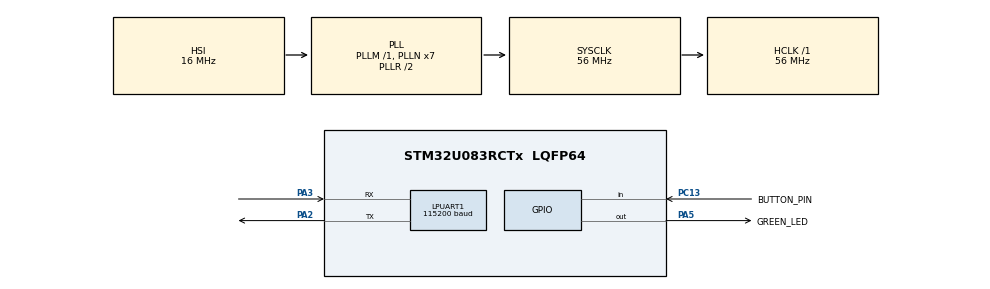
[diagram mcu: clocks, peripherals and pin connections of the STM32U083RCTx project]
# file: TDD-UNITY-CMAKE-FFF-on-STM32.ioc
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LPUART1.BaudRate=115200
Mcu.Family=STM32U0
Mcu.Name=STM32U083RCTx
Mcu.Package=LQFP64
NVIC.PriorityGroup=NVIC_PRIORITYGROUP_2
PA13\ (SWDIO).GPIO_Label=SWDIO
PA13\ (SWDIO).Mode=Serial_Wire
PA13\ (SWDIO).Signal=DEBUG_JTMS-SWDIO
PA14\ (SWCLK).GPIO_Label=SWCLK
PA14\ (SWCLK).Mode=Serial_Wire
PA14\ (SWCLK).Signal=DEBUG_JTCK-SWCLK
PA2.Mode=Asynchronous
PA2.Signal=LPUART1_TX
PA3.Mode=Asynchronous
PA3.Signal=LPUART1_RX
PA5.GPIO_Label=GREEN_LED
PA5.Signal=GPIO_Output
PC13.GPIO_Label=BUTTON_PIN
PC13.Signal=GPIO_Input
ProjectManager.HeapSize=0x200
ProjectManager.StackSize=0x400
ProjectManager.TargetToolchain=CMake
RCC.ADCFreq_Value=56000000
RCC.AHBFreq_Value=56000000
RCC.CortexFreq_Value=56000000
RCC.HCLKFreq_Value=56000000
RCC.HSE_VALUE=4000000
RCC.HSI48_VALUE=48000000
RCC.HSI_VALUE=16000000
RCC.LSE_VALUE=32768
RCC.MSI_VALUE=4000000
RCC.PLLN=7
RCC.SYSCLKFreq_VALUE=56000000
RCC.SYSCLKSource=RCC_SYSCLKSOURCE_PLLCLK
RCC.VCOOutputFreq_Value=112000000
VP_PWR_VS_SECSignals.Mode=Security/Privilege
board=NUCLEO-U083RC

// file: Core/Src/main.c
/* USER CODE BEGIN Header */
/**
  ******************************************************************************
  * @file           : main.c
  * @brief          : Main program body
  ******************************************************************************
  * @attention
  *
  * Copyright (c) 2025 STMicroelectronics.
  * All rights reserved.
  *
  * This software is licensed under terms that can be found in the LICENSE file
  * in the root directory of this software component.
  * If no LICENSE file comes with this software, it is provided AS-IS.
  *
  ******************************************************************************
  */
/* USER CODE END Header */
#include "main.h"
#include "usart.h"
#include "gpio.h"

/* USER CODE BEGIN Includes */
#include "ledDriver.h"
/* USER CODE END Includes */

void SystemClock_Config(void);

int main(void)
{

  /* MCU Configuration--------------------------------------------------------*/

  /* Reset of all peripherals, Initializes the Flash interface and the Systick. */
  HAL_Init();

  /* Configure the system clock */
  SystemClock_Config();

  /* Initialize all configured peripherals */
  MX_GPIO_Init();
  MX_LPUART1_UART_Init();
  /* USER CODE BEGIN 2 */
  ledDriver_Init(GREEN_LED_Pin, GREEN_LED_GPIO_Port);
  /* USER CODE END 2 */

  /* Infinite loop */
  /* USER CODE BEGIN WHILE */
  while (1)
  {
    ledDriver_ledOn();
    HAL_Delay(500); // Turn LED on for 500 ms
    ledDriver_ledOff();
    HAL_Delay(500); // Turn LED off for 500 ms
    /* USER CODE END WHILE */

  }
}

void SystemClock_Config(void)
{
  RCC_OscInitTypeDef RCC_OscInitStruct = {0};
  RCC_ClkInitTypeDef RCC_ClkInitStruct = {0};

  /** Configure the main internal regulator output voltage
  */
  HAL_PWREx_ControlVoltageScaling(PWR_REGULATOR_VOLTAGE_SCALE1);

  /** Initializes the RCC Oscillators according to the specified parameters
  * in the RCC_OscInitTypeDef structure.
  */
  RCC_OscInitStruct.OscillatorType = RCC_OSCILLATORTYPE_HSI;
  RCC_OscInitStruct.HSIState = RCC_HSI_ON;
  RCC_OscInitStruct.HSICalibrationValue = RCC_HSICALIBRATION_DEFAULT;
  RCC_OscInitStruct.PLL.PLLState = RCC_PLL_ON;
  RCC_OscInitStruct.PLL.PLLSource = RCC_PLLSOURCE_HSI;
  RCC_OscInitStruct.PLL.PLLM = RCC_PLLM_DIV1;
  RCC_OscInitStruct.PLL.PLLN = 7;
  RCC_OscInitStruct.PLL.PLLP = RCC_PLLP_DIV2;
  RCC_OscInitStruct.PLL.PLLQ = RCC_PLLQ_DIV2;
  RCC_OscInitStruct.PLL.PLLR = RCC_PLLR_DIV2;
  if (HAL_RCC_OscConfig(&RCC_OscInitStruct) != HAL_OK)
  {
    Error_Handler();
  }

  /** Initializes the CPU, AHB and APB buses clocks
  */
  RCC_ClkInitStruct.ClockType = RCC_CLOCKTYPE_HCLK|RCC_CLOCKTYPE_SYSCLK
                              |RCC_CLOCKTYPE_PCLK1;
  RCC_ClkInitStruct.SYSCLKSource = RCC_SYSCLKSOURCE_PLLCLK;
  RCC_ClkInitStruct.AHBCLKDivider = RCC_SYSCLK_DIV1;
  RCC_ClkInitStruct.APB1CLKDivider = RCC_HCLK_DIV1;

  if (HAL_RCC_ClockConfig(&RCC_ClkInitStruct, FLASH_LATENCY_2) != HAL_OK)
  {
    Error_Handler();
  }
}

void Error_Handler(void)
{
  __disable_irq();
  while (1)
  {
  }
}
